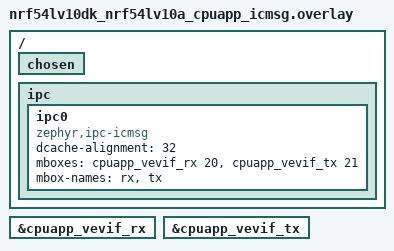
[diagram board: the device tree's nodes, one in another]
/*
 * Copyright (c) 2025 Nordic Semiconductor ASA
 *
 * SPDX-License-Identifier: LicenseRef-Nordic-5-Clause
 */

/ {
	chosen {
		/delete-property/ zephyr,bt-hci;
	};

	ipc {
		ipc0: ipc0 {
			compatible = "zephyr,ipc-icmsg";
			dcache-alignment = <32>;
			/delete-property/ tx-blocks;
			/delete-property/ rx-blocks;
			mboxes = <&cpuapp_vevif_rx 20>, <&cpuapp_vevif_tx 21>;
			mbox-names = "rx", "tx";
			status = "okay";
		};
	};
};

&cpuapp_vevif_rx {
	status = "okay";
};

&cpuapp_vevif_tx {
	status = "okay";
};
